# MSP432P401M register map
Vendor: Texas Instruments; File version: 3.230
Registers are 32-bit, read-write, reset 0x0 unless marked. A register's access mark holds for its fields unless they carry their own. Offsets are from the block's base; [hi:lo] are bit positions; 'fields as' and 'values as' point back to an identical list.

## RTC_C
Base 0x40004400
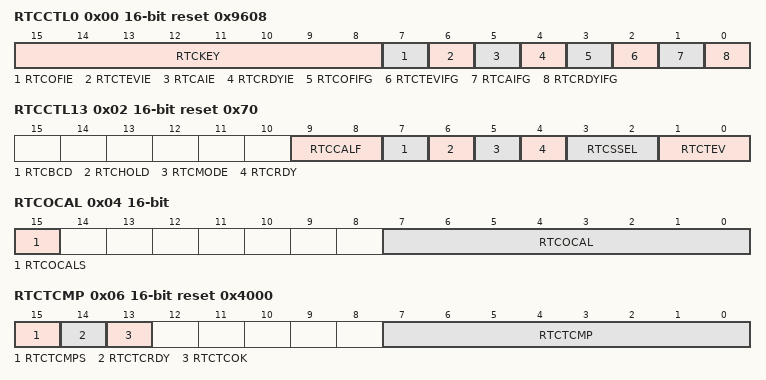
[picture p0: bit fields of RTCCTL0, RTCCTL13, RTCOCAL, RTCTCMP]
0x00 RTCCTL0 16-bit reset 0x9608
  [15:8] RTCKEY — Real-time clock key
  [7] RTCOFIE — 32-kHz crystal oscillator fault interrupt enable
    0=Interrupt not enabled; 1=Interrupt enabled (LPM3/LPM3.5 wake-up enabled)
  [6] RTCTEVIE — Real-time clock time event interrupt enable
    values as RTCOFIE
  [5] RTCAIE — Real-time clock alarm interrupt enable
    values as RTCOFIE
  [4] RTCRDYIE — Real-time clock ready interrupt enable
    0=Interrupt not enabled; 1=Interrupt enabled
  [3] RTCOFIFG — 32-kHz crystal oscillator fault interrupt flag
    0=No interrupt pending; 1=Interrupt pending. A 32-kHz crystal oscillator fault occurred after last reset.
  [2] RTCTEVIFG — Real-time clock time event interrupt flag
    0=No time event occurred; 1=Time event occurred
  [1] RTCAIFG — Real-time clock alarm interrupt flag
    0=No time event occurred; 1=Time event occurred
  [0] RTCRDYIFG — Real-time clock ready interrupt flag
    0=RTC cannot be read safely; 1=RTC can be read safely
0x02 RTCCTL13 16-bit reset 0x70
  [9:8] RTCCALF — Real-time clock calibration frequency
    0=No frequency output to RTCCLK pin; 1=512 Hz; 2=256 Hz; 3=1 Hz
  [7] RTCBCD — Real-time clock BCD select
    0=Binary (hexadecimal) code selected; 1=Binary coded decimal (BCD) code selected
  [6] RTCHOLD — Real-time clock hold
    0=Real-time clock is operational; 1=When set, the calendar is stopped as well as the prescale counters, RT0PS and RT1PS are don't care
  [5] RTCMODE ro
    on read: 1=Calendar mode. Always reads a value of 1.
  [4] RTCRDY ro — Real-time clock ready
    on read: 0=RTC time values in transition; 1=RTC time values safe for reading. This bit indicates when the real-time clock time values are safe for reading.
  [3:2] RTCSSEL — Real-time clock source select
    0=BCLK
  [1:0] RTCTEV — Real-time clock time event
    0=Minute changed; 1=Hour changed; 2=Every day at midnight (00:00); 3=Every day at noon (12:00)
0x04 RTCOCAL 16-bit
  [15] RTCOCALS — Real-time clock offset error calibration sign
    0=Down calibration. Frequency adjusted down.; 1=Up calibration. Frequency adjusted up.
  [7:0] RTCOCAL — Real-time clock offset error calibration
0x06 RTCTCMP 16-bit reset 0x4000
  [15] RTCTCMPS — Real-time clock temperature compensation sign
    0=Down calibration. Frequency adjusted down; 1=Up calibration. Frequency adjusted up
  [14] RTCTCRDY ro — Real-time clock temperature compensation ready
  [13] RTCTCOK ro — Real-time clock temperature compensation write OK
    on read: 0=Write to RTCTCMPx is unsuccessful; 1=Write to RTCTCMPx is successful
  [7:0] RTCTCMP — Real-time clock temperature compensation
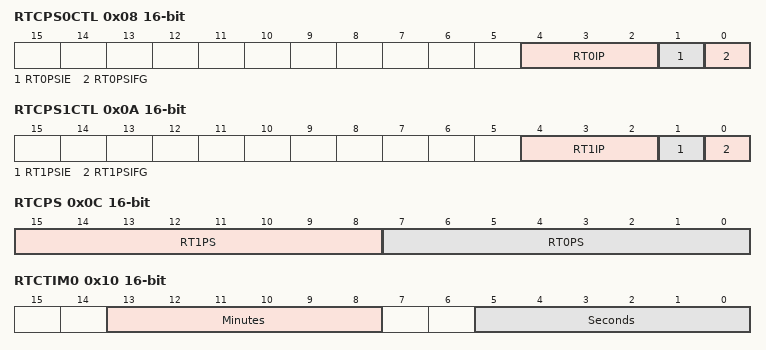
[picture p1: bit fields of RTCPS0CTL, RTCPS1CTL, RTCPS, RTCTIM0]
0x08 RTCPS0CTL 16-bit — Real-Time Clock Prescale Timer 0 Control Register
  [4:2] RT0IP — Prescale timer 0 interrupt interval
    0=Divide by 2; 1=Divide by 4; 2=Divide by 8; 3=Divide by 16; 4=Divide by 32; 5=Divide by 64; 6=Divide by 128; 7=Divide by 256
  [1] RT0PSIE — Prescale timer 0 interrupt enable
    values as RTCCTL0.RTCOFIE
  [0] RT0PSIFG — Prescale timer 0 interrupt flag
    0=No time event occurred; 1=Time event occurred
0x0A RTCPS1CTL 16-bit — Real-Time Clock Prescale Timer 1 Control Register
  [4:2] RT1IP — Prescale timer 1 interrupt interval
    values as RTCPS0CTL.RT0IP
  [1] RT1PSIE — Prescale timer 1 interrupt enable
    values as RTCCTL0.RTCOFIE
  [0] RT1PSIFG — Prescale timer 1 interrupt flag
    0=No time event occurred; 1=Time event occurred
0x0C RTCPS 16-bit reset not defined — Real-Time Clock Prescale Timer Counter Register
  [15:8] RT1PS — Prescale timer 1 counter value
  [7:0] RT0PS — Prescale timer 0 counter value
0x0E RTCIV 16-bit ro — Real-Time Clock Interrupt Vector Register
  [15:0] RTCIV — Real-time clock interrupt vector value
    on read: 0=No interrupt pending; 2=Interrupt Source: RTC oscillator failure; Interrupt Flag: RTCOFIFG; Interrupt Priority: Highest; 4=Interrupt Source: RTC ready; Interrupt Flag: RTCRDYIFG; 6=Interrupt Source: RTC interval timer; Interrupt Flag: RTCTEVIFG; 8=Interrupt Source: RTC user alarm; Interrupt Flag: RTCAIFG; 10=Interrupt Source: RTC prescaler 0; Interrupt Flag: RT0PSIFG; 12=Interrupt Source: RTC prescaler 1; Interrupt Flag: RT1PSIFG
0x10 RTCTIM0 16-bit (reset mask 0xC0C0) — RTCTIM0 Register Hexadecimal Format
  [13:8] Minutes — Minutes (0 to 59)
  [5:0] Seconds — Seconds (0 to 59)
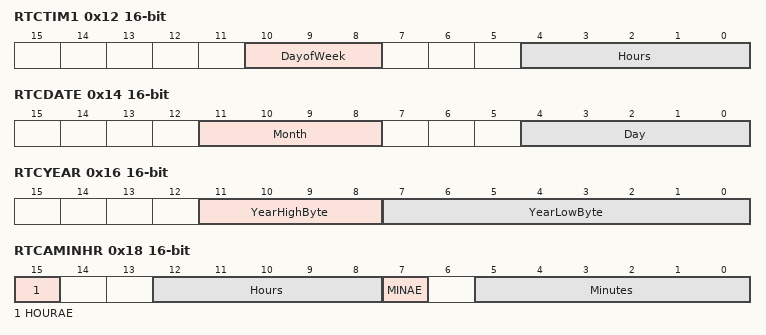
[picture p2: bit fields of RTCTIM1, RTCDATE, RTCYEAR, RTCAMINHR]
0x12 RTCTIM1 16-bit (reset mask 0xF8E0) — Real-Time Clock Hour, Day of Week
  [10:8] DayofWeek — Day of week (0 to 6)
  [4:0] Hours — Hours (0 to 23)
0x14 RTCDATE 16-bit (reset mask 0xF0E0) — RTCDATE - Hexadecimal Format
  [11:8] Month — Month (1 to 12)
  [4:0] Day — Day of month (1 to 28, 29, 30, 31)
0x16 RTCYEAR 16-bit (reset mask 0xF000) — RTCYEAR Register Hexadecimal Format
  [11:8] YearHighByte — Year high byte. Valid values for Year are 0 to 4095.
  [7:0] YearLowByte — Year low byte. Valid values for Year are 0 to 4095.
0x18 RTCAMINHR 16-bit (reset mask 0x6040) — RTCMINHR - Hexadecimal Format
  [15] HOURAE — Alarm enable
  [12:8] Hours — Hours (0 to 23)
  [7] MINAE — Alarm enable
  [5:0] Minutes — Minutes (0 to 59)
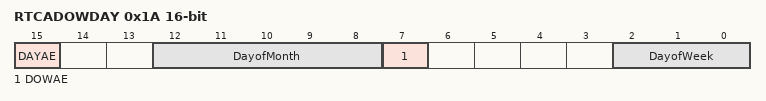
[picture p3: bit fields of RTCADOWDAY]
0x1A RTCADOWDAY 16-bit (reset mask 0x6078) — RTCADOWDAY - Hexadecimal Format
  [15] DAYAE — Alarm enable
  [12:8] DayofMonth — Day of month (1 to 28, 29, 30, 31)
  [7] DOWAE — Alarm enable
  [2:0] DayofWeek — Day of week (0 to 6)
0x1C RTCBIN2BCD 16-bit — Binary-to-BCD Conversion Register
  [15:0] BIN2BCD — bin to bcd conversion
0x1E RTCBCD2BIN 16-bit — BCD-to-Binary Conversion Register
  [15:0] BCD2BIN — bcd to bin conversion
